# RK3399-AP register map
File version: 1
CPU: CA7 r0p1, little endian, MPU, FPU, I-cache, D-cache, VTOR, 4 interrupt priority bits, 0 interrupts
Registers are 32-bit, read-write, reset 0x0 unless marked. A register's access mark holds for its fields unless they carry their own. Offsets are from the block's base; [hi:lo] are bit positions; 'fields as' and 'values as' point back to an identical list.

## CRU (part 1 of 3)
Base 0xFF760000
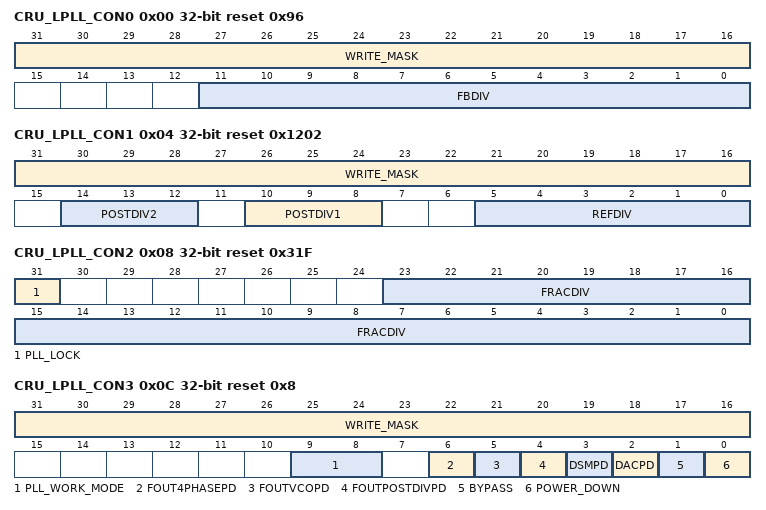
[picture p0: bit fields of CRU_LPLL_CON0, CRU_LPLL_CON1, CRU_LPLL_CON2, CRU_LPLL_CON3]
0x00 CRU_LPLL_CON0 access per field reset 0x96 — LPLL configuration register0
  [31:16] WRITE_MASK wo — write mask bits When every bit HIGH, enable the writing corresponding bit When every bit LOW, don\'t care the writing corresponding bit
  [11:0] FBDIV rw — Feedback Divide Value Valid divider settings are: [16, 3200] in integer mode [20, 320] in fractional mode Tips: no plus one operation
0x04 CRU_LPLL_CON1 access per field reset 0x1202 — LPLL configuration register1
  [31:16] WRITE_MASK wo — write mask bits When every bit HIGH, enable the writing corresponding bit When every bit LOW, don\'t care the writing corresponding bit
  [14:12] POSTDIV2 rw — Second Post Divide Value (1-7)
  [10:8] POSTDIV1 rw — First Post Divide Value (1-7)
  [5:0] REFDIV rw — Reference Clock Divide Value (1-63)
0x08 CRU_LPLL_CON2 access per field reset 0x31F — LPLL configuration register2
  [31] PLL_LOCK ro — PLL lock status 1\'b0: unlock 1\'b1: lock
  [23:0] FRACDIV rw — Fractional part of feedback divide (fraction = FRAC/2^24)
0x0C CRU_LPLL_CON3 access per field reset 0x8 — LPLL configuration register3
  [31:16] WRITE_MASK wo — write mask bits When every bit HIGH, enable the writing corresponding bit When every bit LOW, don\'t care the writing corresponding bit
  [9:8] PLL_WORK_MODE rw — PLL work mode select 2\'b00: Slow mode, clock from external 24MHz/26MHz OSC (default) 2\'b01: Normal mode, clock from PLL output 2\'b10: Deep slow mode, clock from external 32.768kHz
  [6] FOUT4PHASEPD rw — Power down 4-phase clocks and 2X, 3X, 4X clocks 1\'b0: no power down 1\'b1: power down
  [5] FOUTVCOPD rw — Power down buffered VCO clock 1\'b0: no power down 1\'b1: power down
  [4] FOUTPOSTDIVPD rw — Power down all outputs except for buffered VCO clock 1\'b0: no power down 1\'b1: power down
  [3] DSMPD rw — PLL saturation behavior enable 1\'b0: no power down 1\'b1: power down DSMPD = 1\'b1 ( modulator is disabled, "integer mode")
  [2] DACPD rw — Power down quantization noise cancellation DAC 1\'b0: no power down 1\'b1: power down
  [1] BYPASS rw — PLL Bypass. FREF bypasses PLL to FOUTPOSTDIV 1\'b0: no bypass 1\'b1: bypass
  [0] POWER_DOWN rw — Global power down 1\'b0: no power down 1\'b1: power down
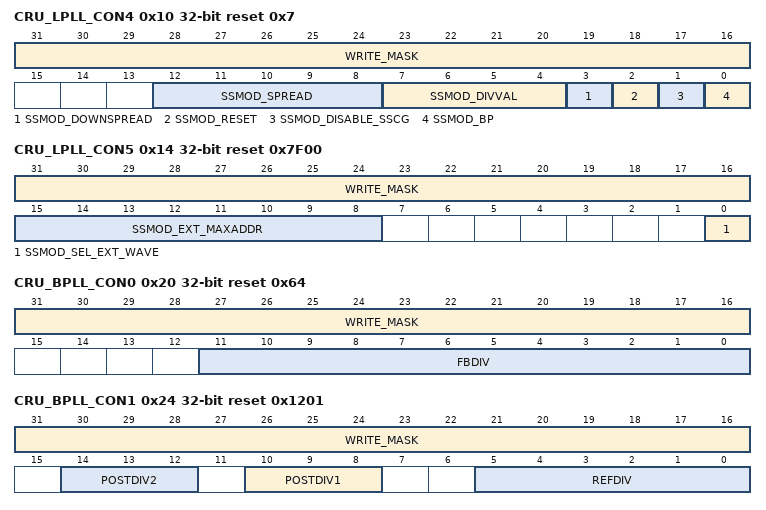
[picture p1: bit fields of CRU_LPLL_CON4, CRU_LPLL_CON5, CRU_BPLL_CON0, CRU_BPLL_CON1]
0x10 CRU_LPLL_CON4 access per field reset 0x7 — LPLL configuration register4
  [31:16] WRITE_MASK wo — write mask bits When every bit HIGH, enable the writing corresponding bit When every bit LOW, don\'t care the writing corresponding bit
  [12:8] SSMOD_SPREAD rw — spread amplitude % = 0.1 * SPREAD[4:0]
  [7:4] SSMOD_DIVVAL rw — Divider required to set the modulation frequency Divider required to set the modulation frequency
  [3] SSMOD_DOWNSPREAD rw — Selects center spread or downs pread 1\'b0: center spread 1\'b1: down spread
  [2] SSMOD_RESET rw — Reset modulator state 1\'b0: no reset 1\'b1: reset
  [1] SSMOD_DISABLE_SSCG rw — Bypass SSMOD by module 1\'b0: no bypass 1\'b1: bypass
  [0] SSMOD_BP rw — Bypass SSMOD by integration 1\'b0: no bypass 1\'b1: bypass
0x14 CRU_LPLL_CON5 access per field reset 0x7F00 — LPLL configuration register5
  [31:16] WRITE_MASK wo — write mask bits When every bit HIGH, enable the writing corresponding bit When every bit LOW, don\'t care the writing corresponding bit
  [15:8] SSMOD_EXT_MAXADDR rw — External wave table data inputs (0-255)
  [0] SSMOD_SEL_EXT_WAVE rw — select external wave 1\'b0: no select ext_wave 1\'b1: select ext_wave
0x20 CRU_BPLL_CON0 access per field reset 0x64 — BPLL configuration register0
  fields as CRU_LPLL_CON0
0x24 CRU_BPLL_CON1 access per field reset 0x1201 — BPLL configuration register1
  fields as CRU_LPLL_CON1
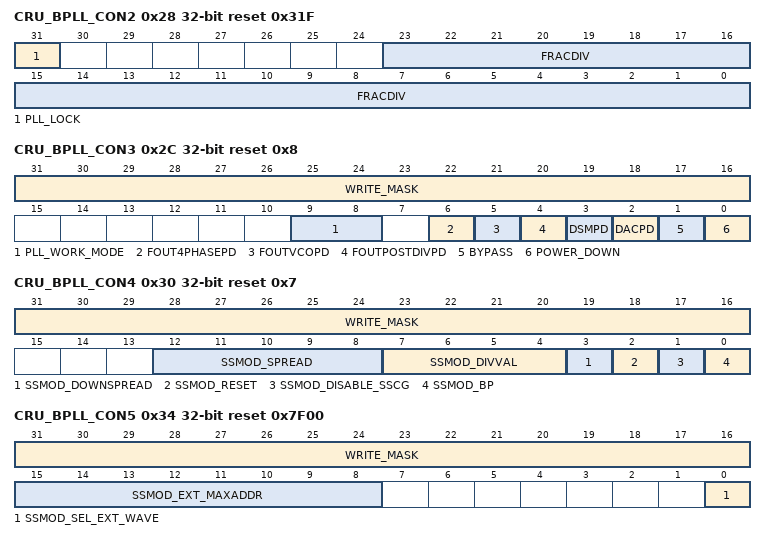
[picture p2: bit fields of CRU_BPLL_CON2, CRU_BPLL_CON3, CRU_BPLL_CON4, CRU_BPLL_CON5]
0x28 CRU_BPLL_CON2 access per field reset 0x31F — BPLL configuration register2
  fields as CRU_LPLL_CON2
0x2C CRU_BPLL_CON3 access per field reset 0x8 — BPLL configuration register3
  fields as CRU_LPLL_CON3
0x30 CRU_BPLL_CON4 access per field reset 0x7 — BPLL configuration register4
  fields as CRU_LPLL_CON4
0x34 CRU_BPLL_CON5 access per field reset 0x7F00 — BPLL configuration register5
  fields as CRU_LPLL_CON5
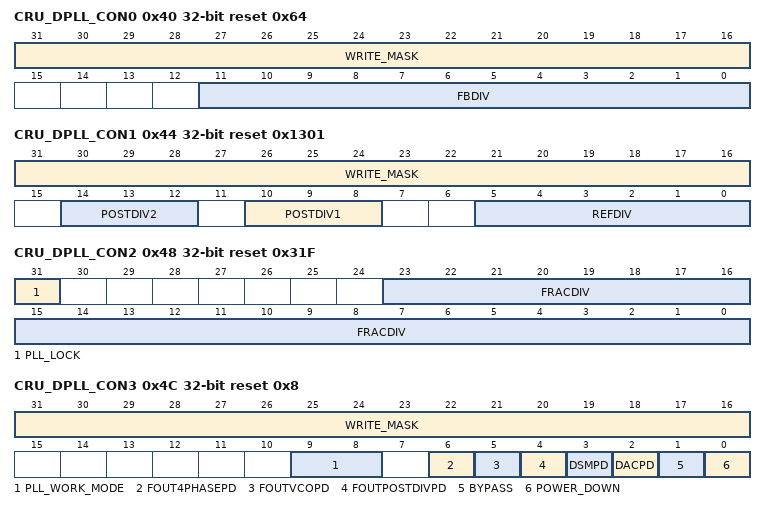
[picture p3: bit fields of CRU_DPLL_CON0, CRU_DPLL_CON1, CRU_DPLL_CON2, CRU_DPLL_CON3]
0x40 CRU_DPLL_CON0 access per field reset 0x64 — DPLL configuration register0
  fields as CRU_LPLL_CON0
0x44 CRU_DPLL_CON1 access per field reset 0x1301 — DPLL configuration register1
  fields as CRU_LPLL_CON1
0x48 CRU_DPLL_CON2 access per field reset 0x31F — DPLL configuration register2
  fields as CRU_LPLL_CON2
0x4C CRU_DPLL_CON3 access per field reset 0x8 — DPLL configuration register3
  fields as CRU_LPLL_CON3
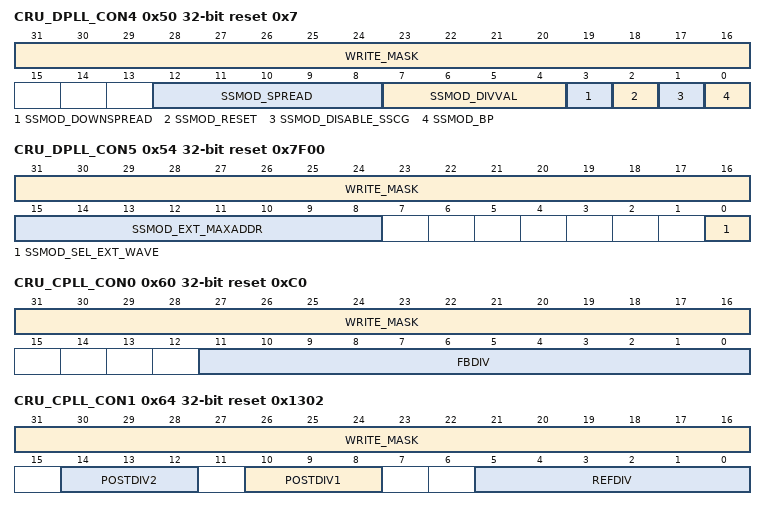
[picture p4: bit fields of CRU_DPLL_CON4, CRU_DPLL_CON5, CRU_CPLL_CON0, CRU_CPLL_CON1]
0x50 CRU_DPLL_CON4 access per field reset 0x7 — DPLL configuration register4
  fields as CRU_LPLL_CON4
0x54 CRU_DPLL_CON5 access per field reset 0x7F00 — DPLL configuration register5
  fields as CRU_LPLL_CON5
0x60 CRU_CPLL_CON0 access per field reset 0xC0 — CPLL configuration register0
  fields as CRU_LPLL_CON0
0x64 CRU_CPLL_CON1 access per field reset 0x1302 — CPLL configuration register1
  fields as CRU_LPLL_CON1
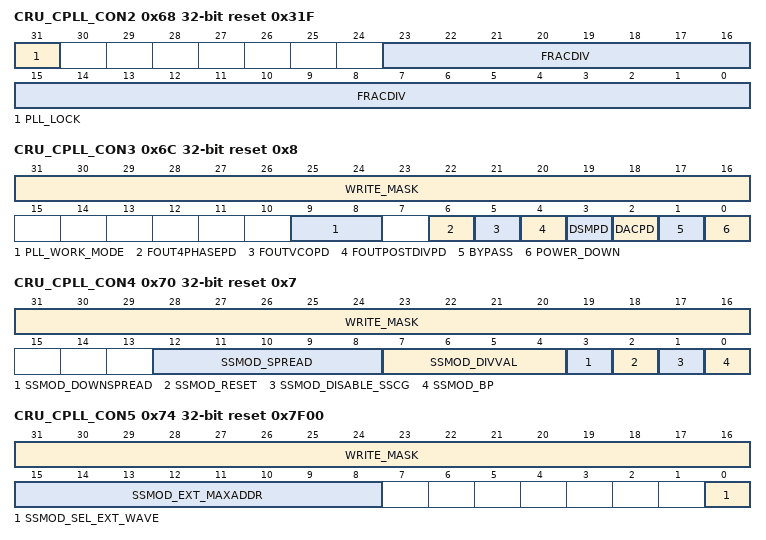
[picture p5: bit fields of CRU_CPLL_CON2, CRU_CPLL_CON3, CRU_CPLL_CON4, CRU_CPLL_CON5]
0x68 CRU_CPLL_CON2 access per field reset 0x31F — CPLL configuration register2
  fields as CRU_LPLL_CON2
0x6C CRU_CPLL_CON3 access per field reset 0x8 — CPLL configuration register3
  fields as CRU_LPLL_CON3
0x70 CRU_CPLL_CON4 access per field reset 0x7 — CPLL configuration register4
  fields as CRU_LPLL_CON4
0x74 CRU_CPLL_CON5 access per field reset 0x7F00 — CPLL configuration register5
  fields as CRU_LPLL_CON5
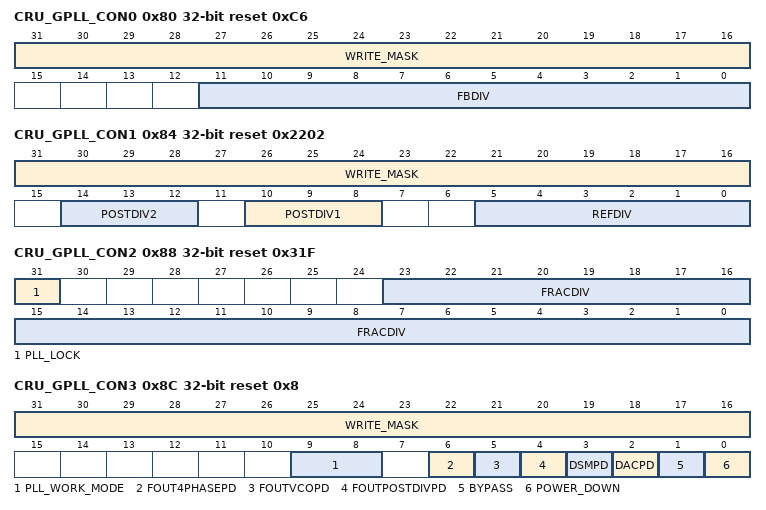
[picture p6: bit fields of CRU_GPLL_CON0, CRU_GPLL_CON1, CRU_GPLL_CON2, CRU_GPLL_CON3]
0x80 CRU_GPLL_CON0 access per field reset 0xC6 — GPLL configuration register0
  fields as CRU_LPLL_CON0
0x84 CRU_GPLL_CON1 access per field reset 0x2202 — GPLL configuration register1
  fields as CRU_LPLL_CON1
0x88 CRU_GPLL_CON2 access per field reset 0x31F — GPLL configuration register2
  fields as CRU_LPLL_CON2
0x8C CRU_GPLL_CON3 access per field reset 0x8 — GPLL configuration register3
  fields as CRU_LPLL_CON3
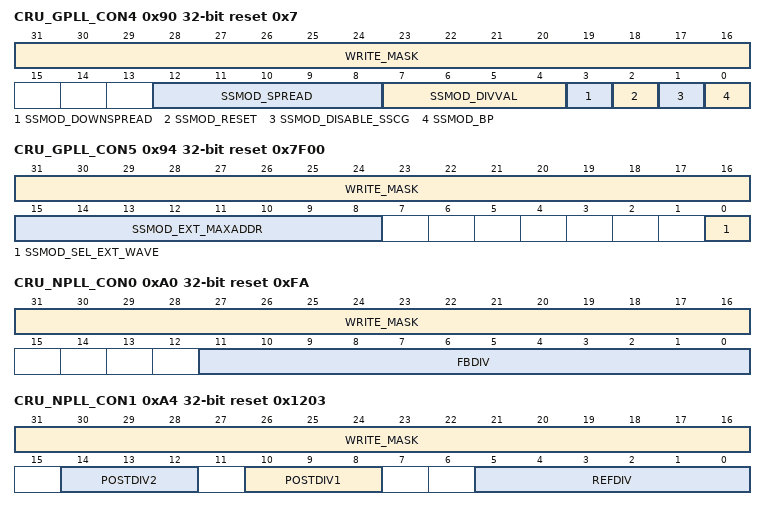
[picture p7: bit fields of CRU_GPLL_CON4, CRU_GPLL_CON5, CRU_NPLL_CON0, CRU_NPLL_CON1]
0x90 CRU_GPLL_CON4 access per field reset 0x7 — GPLL configuration register4
  fields as CRU_LPLL_CON4
0x94 CRU_GPLL_CON5 access per field reset 0x7F00 — GPLL configuration register5
  fields as CRU_LPLL_CON5
0xA0 CRU_NPLL_CON0 access per field reset 0xFA — NPLL configuration register0
  fields as CRU_LPLL_CON0
0xA4 CRU_NPLL_CON1 access per field reset 0x1203 — NPLL configuration register1
  fields as CRU_LPLL_CON1
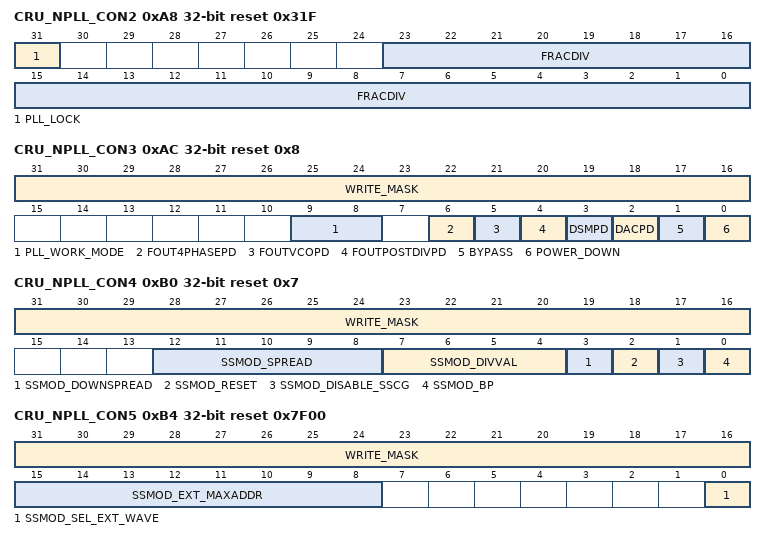
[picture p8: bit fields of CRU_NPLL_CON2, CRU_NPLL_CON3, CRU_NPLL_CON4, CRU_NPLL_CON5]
0xA8 CRU_NPLL_CON2 access per field reset 0x31F — NPLL configuration register2
  fields as CRU_LPLL_CON2
0xAC CRU_NPLL_CON3 access per field reset 0x8 — NPLL configuration register3
  fields as CRU_LPLL_CON3
0xB0 CRU_NPLL_CON4 access per field reset 0x7 — NPLL configuration register4
  fields as CRU_LPLL_CON4
0xB4 CRU_NPLL_CON5 access per field reset 0x7F00 — NPLL configuration register5
  fields as CRU_LPLL_CON5
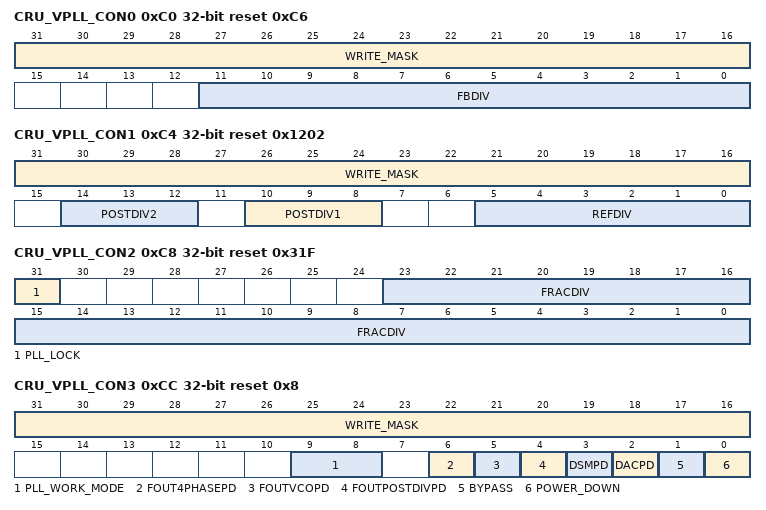
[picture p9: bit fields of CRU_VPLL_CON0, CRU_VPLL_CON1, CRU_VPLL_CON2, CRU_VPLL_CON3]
0xC0 CRU_VPLL_CON0 access per field reset 0xC6 — VPLL configuration register0
  fields as CRU_LPLL_CON0
0xC4 CRU_VPLL_CON1 access per field reset 0x1202 — VPLL configuration register1
  fields as CRU_LPLL_CON1
0xC8 CRU_VPLL_CON2 access per field reset 0x31F — VPLL configuration register2
  fields as CRU_LPLL_CON2
0xCC CRU_VPLL_CON3 access per field reset 0x8 — VPLL configuration register3
  fields as CRU_LPLL_CON3
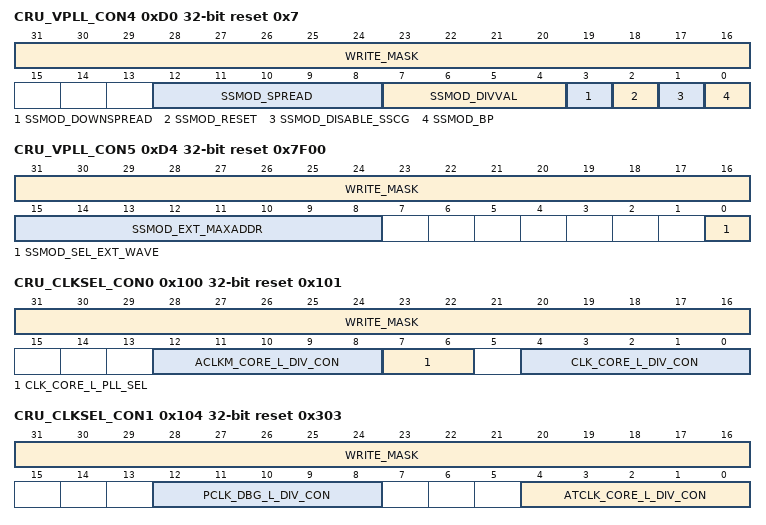
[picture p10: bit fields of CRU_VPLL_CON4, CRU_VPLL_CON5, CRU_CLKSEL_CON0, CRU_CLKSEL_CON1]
0xD0 CRU_VPLL_CON4 access per field reset 0x7 — VPLL configuration register4
  fields as CRU_LPLL_CON4
0xD4 CRU_VPLL_CON5 access per field reset 0x7F00 — VPLL configuration register5
  fields as CRU_LPLL_CON5
0x100 CRU_CLKSEL_CON0 access per field reset 0x101 — Internal clock select and divide register0
  [31:16] WRITE_MASK wo — write mask bits When every bit HIGH, enable the writing corresponding bit When every bit LOW, don\'t care the writing corresponding bit
  [12:8] ACLKM_CORE_L_DIV_CON rw — aclkm_core_l divider control register clk=clk_src/(div_con+1)
  [7:6] CLK_CORE_L_PLL_SEL rw — clk_core_l clock source select control register 2\'b00:LPLL 2\'b01:BPLL 2\'b10:DPLL 2\'b11:GPLL
  [4:0] CLK_CORE_L_DIV_CON rw — clk_core_l divider control register clk=clk_src/(div_con+1)
0x104 CRU_CLKSEL_CON1 access per field reset 0x303 — Internal clock select and divide register1
  [31:16] WRITE_MASK wo — write mask bits When every bit HIGH, enable the writing corresponding bit When every bit LOW, don\'t care the writing corresponding bit
  [12:8] PCLK_DBG_L_DIV_CON rw — pclk_dbg_l divider control register clk=clk_src/(div_con+1)
  [4:0] ATCLK_CORE_L_DIV_CON rw — atclk_core_l divider control register clk=clk_src/(div_con+1)
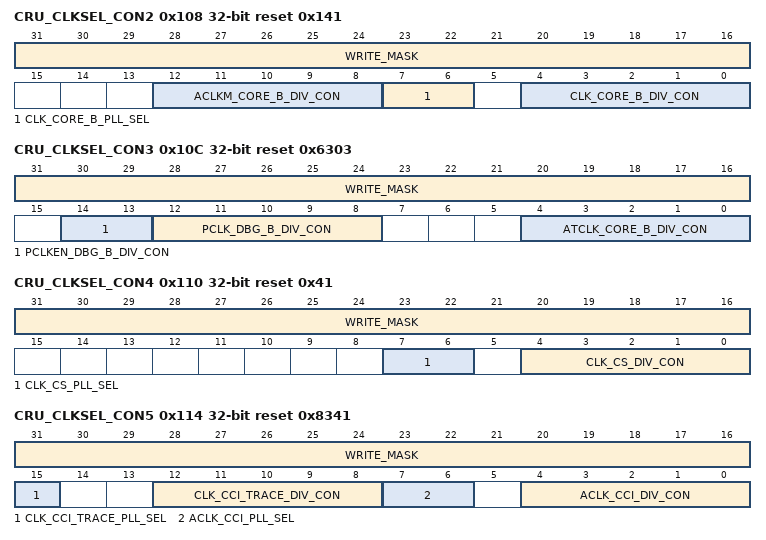
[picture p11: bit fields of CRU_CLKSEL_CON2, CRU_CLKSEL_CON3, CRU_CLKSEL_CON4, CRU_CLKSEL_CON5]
0x108 CRU_CLKSEL_CON2 access per field reset 0x141 — Internal clock select and divide register2
  [31:16] WRITE_MASK wo — write mask bits When every bit HIGH, enable the writing corresponding bit When every bit LOW, don\'t care the writing corresponding bit
  [12:8] ACLKM_CORE_B_DIV_CON rw — aclkm_core_b divider control register clk=clk_src/(div_con+1)
  [7:6] CLK_CORE_B_PLL_SEL rw — clk_core_b clock source select control register 2\'b00:LPLL 2\'b01:BPLL 2\'b10:DPLL 2\'b11:GPLL
  [4:0] CLK_CORE_B_DIV_CON rw — clk_core_b divider control register clk=clk_src/(div_con+1)
0x10C CRU_CLKSEL_CON3 access per field reset 0x6303 — Internal clock select and divide register3
  [31:16] WRITE_MASK wo — write mask bits When every bit HIGH, enable the writing corresponding bit When every bit LOW, don\'t care the writing corresponding bit
  [14:13] PCLKEN_DBG_B_DIV_CON rw — pclken_dbg_b divider control register clk=clk_src/(div_con+1)
  [12:8] PCLK_DBG_B_DIV_CON rw — pclk_dbg_b divider control register clk=clk_src/(div_con+1)
  [4:0] ATCLK_CORE_B_DIV_CON rw — atclk_core_b divider control register clk=clk_src/(div_con+1)
0x110 CRU_CLKSEL_CON4 access per field reset 0x41 — Internal clock select and divide register4
  [31:16] WRITE_MASK wo — write mask bits When every bit HIGH, enable the writing corresponding bit When every bit LOW, don\'t care the writing corresponding bit
  [7:6] CLK_CS_PLL_SEL rw — clk_cs clock source select control register 2\'b00:CPLL 2\'b01:GPLL 2\'b1x:NPLL
  [4:0] CLK_CS_DIV_CON rw — clk_cs divider control register clk=clk_src/(div_con+1)
0x114 CRU_CLKSEL_CON5 access per field reset 0x8341 — Internal clock select and divide register5
  [31:16] WRITE_MASK wo — write mask bits When every bit HIGH, enable the writing corresponding bit When every bit LOW, don\'t care the writing corresponding bit
  [15] CLK_CCI_TRACE_PLL_SEL rw — clk_cci_trace clock source select control register 1\'b0:CPLL 1\'b1:GPLL
  [12:8] CLK_CCI_TRACE_DIV_CON rw — clk_cci_trace divider control register clk=clk_src/(div_con+1)
  [7:6] ACLK_CCI_PLL_SEL rw — aclk_cci clock source select control register 2\'b00:CPLL 2\'b01:GPLL 2\'b10:NPLL 2\'b11:VPLL
  [4:0] ACLK_CCI_DIV_CON rw — aclk_cci divider control register clk=clk_src/(div_con+1)
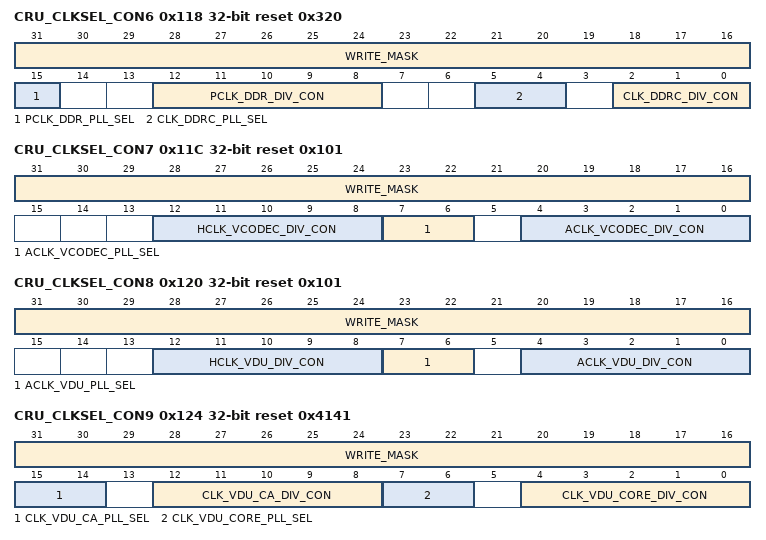
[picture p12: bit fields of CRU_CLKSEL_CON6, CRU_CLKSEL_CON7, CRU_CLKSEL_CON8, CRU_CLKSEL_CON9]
0x118 CRU_CLKSEL_CON6 access per field reset 0x320 — Internal clock select and divide register6
  [31:16] WRITE_MASK wo — write mask bits When every bit HIGH, enable the writing corresponding bit When every bit LOW, don\'t care the writing corresponding bit
  [15] PCLK_DDR_PLL_SEL rw — pclk_ddr clock source select control register 1\'b0:CPLL 1\'b1:GPLL
  [12:8] PCLK_DDR_DIV_CON rw — pclk_ddr divider control register clk=clk_src/(div_con+1)
  [5:4] CLK_DDRC_PLL_SEL rw — clk_ddrc clock source select control register 2\'b00:LPLL 2\'b01:BPLL 2\'b10:DPLL 2\'b11:GPLL
  [2:0] CLK_DDRC_DIV_CON rw — clk_ddrc divider control register clk=clk_src/(div_con+1)
0x11C CRU_CLKSEL_CON7 access per field reset 0x101 — Internal clock select and divide register7
  [31:16] WRITE_MASK wo — write mask bits When every bit HIGH, enable the writing corresponding bit When every bit LOW, don\'t care the writing corresponding bit
  [12:8] HCLK_VCODEC_DIV_CON rw — hclk_vcodec divider control register clk=clk_src/(div_con+1)
  [7:6] ACLK_VCODEC_PLL_SEL rw — aclk_vcodec clock source select control register 2\'b00:CPLL 2\'b01:GPLL 2\'b10:NPLL 2\'b11:PPLL
  [4:0] ACLK_VCODEC_DIV_CON rw — aclk_vcodec divider control register clk=clk_src/(div_con+1)
0x120 CRU_CLKSEL_CON8 access per field reset 0x101 — Internal clock select and divide register8
  [31:16] WRITE_MASK wo — write mask bits When every bit HIGH, enable the writing corresponding bit When every bit LOW, don\'t care the writing corresponding bit
  [12:8] HCLK_VDU_DIV_CON rw — hclk_vdu divider control register clk=clk_src/(div_con+1)
  [7:6] ACLK_VDU_PLL_SEL rw — aclk_vdu clock source select control register 2\'b00:CPLL 2\'b01:GPLL 2\'b10:NPLL 2\'b11:PPLL
  [4:0] ACLK_VDU_DIV_CON rw — aclk_vdu divider control register clk=clk_src/(div_con+1)
0x124 CRU_CLKSEL_CON9 access per field reset 0x4141 — Internal clock select and divide register9
  [31:16] WRITE_MASK wo — write mask bits When every bit HIGH, enable the writing corresponding bit When every bit LOW, don\'t care the writing corresponding bit
  [15:14] CLK_VDU_CA_PLL_SEL rw — clk_vdu_ca clock source select control register 2\'b00:CPLL 2\'b01:GPLL 2\'b1x:NPLL
  [12:8] CLK_VDU_CA_DIV_CON rw — clk_vdu_ca divider control register clk=clk_src/(div_con+1)
  [7:6] CLK_VDU_CORE_PLL_SEL rw — clk_vdu_core clock source select control register 2\'b00:CPLL 2\'b01:GPLL 2\'b1x:NPLL
  [4:0] CLK_VDU_CORE_DIV_CON rw — clk_vdu_core divider control register clk=clk_src/(div_con+1)
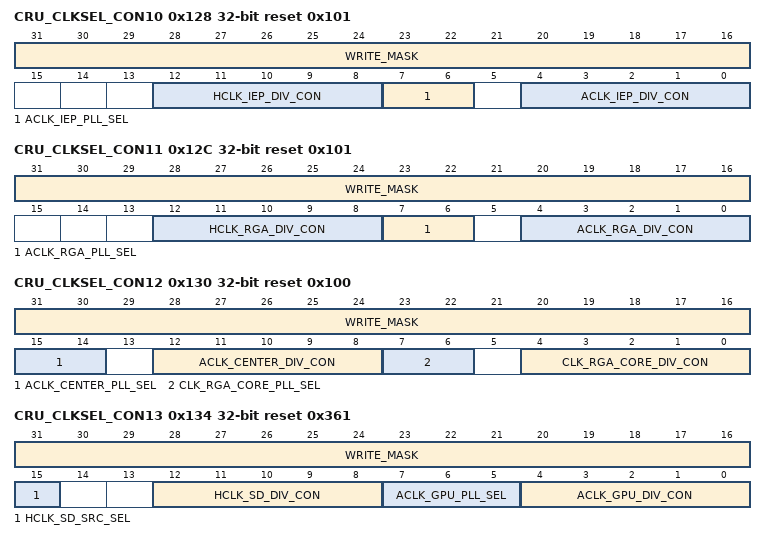
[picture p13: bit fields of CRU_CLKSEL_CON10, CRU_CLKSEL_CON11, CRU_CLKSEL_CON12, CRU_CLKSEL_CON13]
0x128 CRU_CLKSEL_CON10 access per field reset 0x101 — Internal clock select and divide register10
  [31:16] WRITE_MASK wo — write mask bits When every bit HIGH, enable the writing corresponding bit When every bit LOW, don\'t care the writing corresponding bit
  [12:8] HCLK_IEP_DIV_CON rw — hclk_iep divider control register clk=clk_src/(div_con+1)
  [7:6] ACLK_IEP_PLL_SEL rw — aclk_iep clock source select control register 2\'b00:CPLL 2\'b01:GPLL 2\'b10:NPLL 2\'b11:PPLL
  [4:0] ACLK_IEP_DIV_CON rw — aclk_iep divider control register clk=clk_src/(div_con+1)
0x12C CRU_CLKSEL_CON11 access per field reset 0x101 — Internal clock select and divide register11
  [31:16] WRITE_MASK wo — write mask bits When every bit HIGH, enable the writing corresponding bit When every bit LOW, don\'t care the writing corresponding bit
  [12:8] HCLK_RGA_DIV_CON rw — hclk_rga divider control register clk=clk_src/(div_con+1)
  [7:6] ACLK_RGA_PLL_SEL rw — aclk_rga clock source select control register 2\'b00:CPLL 2\'b01:GPLL 2\'b10:NPLL 2\'b11:PPLL
  [4:0] ACLK_RGA_DIV_CON rw — aclk_rga divider control register clk=clk_src/(div_con+1)
0x130 CRU_CLKSEL_CON12 access per field reset 0x100 — Internal clock select and divide register12
  [31:16] WRITE_MASK wo — write mask bits When every bit HIGH, enable the writing corresponding bit When every bit LOW, don\'t care the writing corresponding bit
  [15:14] ACLK_CENTER_PLL_SEL rw — aclk_center clock source select control register 2\'b00:CPLL 2\'b01:GPLL 2\'b1x:NPLL
  [12:8] ACLK_CENTER_DIV_CON rw — aclk_center divider control register clk=clk_src/(div_con+1)
  [7:6] CLK_RGA_CORE_PLL_SEL rw — clk_rga_core clock source select control register 2\'b00:CPLL 2\'b01:GPLL 2\'b10:NPLL 2\'b11:PPLL
  [4:0] CLK_RGA_CORE_DIV_CON rw — clk_rga_core divider control register clk=clk_src/(div_con+1)
0x134 CRU_CLKSEL_CON13 access per field reset 0x361 — Internal clock select and divide register13
  [31:16] WRITE_MASK wo — write mask bits When every bit HIGH, enable the writing corresponding bit When every bit LOW, don\'t care the writing corresponding bit
  [15] HCLK_SD_SRC_SEL rw — hclk_sd clock source select control register 1\'b0:CPLL 1\'b1:GPLL
  [12:8] HCLK_SD_DIV_CON rw — hclk_sd divider control register clk=clk_src/(div_con+1)
  [7:5] ACLK_GPU_PLL_SEL rw — aclk_gpu clock source select control register 3\'b000:PPLL 3\'b001:CPLL 3\'b010:GPLL 3\'b011:NPLL 3\'b100:USB_480M
  [4:0] ACLK_GPU_DIV_CON rw — aclk_gpu divider control register clk=clk_src/(div_con+1)
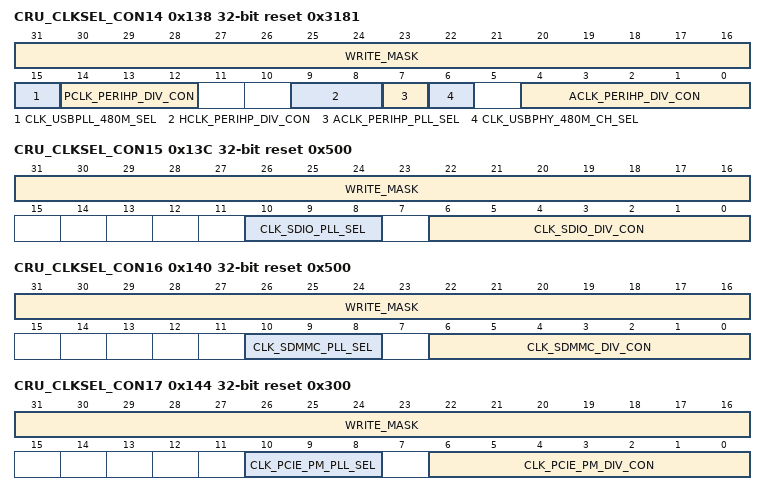
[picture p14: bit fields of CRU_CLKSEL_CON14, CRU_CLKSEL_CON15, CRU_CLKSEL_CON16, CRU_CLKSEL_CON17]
0x138 CRU_CLKSEL_CON14 access per field reset 0x3181 — Internal clock select and divide register14
  [31:16] WRITE_MASK wo — write mask bits When every bit HIGH, enable the writing corresponding bit When every bit LOW, don\'t care the writing corresponding bit
  [15] CLK_USBPLL_480M_SEL rw — clk_usbpll_480m_sel clock select control register 1\'b0:xin_24m 1\'b1:clk_usbphy_480m
  [14:12] PCLK_PERIHP_DIV_CON rw — pclk_perihp divider control register clk=aclk_perihp/(div_con+1)
  [9:8] HCLK_PERIHP_DIV_CON rw — hclk_perihp divider control register clk=aclk_perihp/(div_con+1)
  [7] ACLK_PERIHP_PLL_SEL rw — aclk_perihp clock source select control register 1\'b0:CPLL 1\'b1:GPLL
  [6] CLK_USBPHY_480M_CH_SEL rw — clk_usbphy_480m clock channel select control register 1\'b0:usb_phy0_480m 1\'b1:usb_phy1_480m
  [4:0] ACLK_PERIHP_DIV_CON rw — aclk_perihp divider control register clk=clk_src/(div_con+1)
0x13C CRU_CLKSEL_CON15 access per field reset 0x500 — Internal clock select and divide register15
  [31:16] WRITE_MASK wo — write mask bits When every bit HIGH, enable the writing corresponding bit When every bit LOW, don\'t care the writing corresponding bit
  [10:8] CLK_SDIO_PLL_SEL rw — clk_sdio clock source select control register 3\'b000:CPLL 3\'b001:GPLL 3\'b010:NPLL 3\'b011:PPLL 3\'b100:USB_480M 3\'b101:xin_24m
  [6:0] CLK_SDIO_DIV_CON rw — clk_sdio divider control register clk=clk_src/(div_con+1)
0x140 CRU_CLKSEL_CON16 access per field reset 0x500 — Internal clock select and divide register16
  [31:16] WRITE_MASK wo — write mask bits When every bit HIGH, enable the writing corresponding bit When every bit LOW, don\'t care the writing corresponding bit
  [10:8] CLK_SDMMC_PLL_SEL rw — clk_sdmmc clock source select control register 3\'b000:CPLL 3\'b001:GPLL 3\'b010:NPLL 3\'b011:PPLL 3\'b100:USB_480M 3\'b101:xin_24m
  [6:0] CLK_SDMMC_DIV_CON rw — clk_sdmmc divider control register clk=clk_src/(div_con+1)
0x144 CRU_CLKSEL_CON17 access per field reset 0x300 — Internal clock select and divide register17
  [31:16] WRITE_MASK wo — write mask bits When every bit HIGH, enable the writing corresponding bit When every bit LOW, don\'t care the writing corresponding bit
  [10:8] CLK_PCIE_PM_PLL_SEL rw — clk_pcie_pm clock source select control register 3\'b000:CPLL 3\'b001:GPLL 3\'b010:NPLL 3\'b011:xin_24m 3\'b1xx:reserved
  [6:0] CLK_PCIE_PM_DIV_CON rw — clk_pcie_pm divider control register clk=clk_src/(div_con+1)
0x148 CRU_CLKSEL_CON18 access per field reset 0x4A87 — Internal clock select and divide register18
  [31:16] WRITE_MASK wo — write mask bits When every bit HIGH, enable the writing corresponding bit When every bit LOW, don\'t care the writing corresponding bit
  [15:11] CLK_PCIEPHY_REF100M_DIV_CON rw — clk_pciephy_ref100m divider control register clk=clk_src/(div_con+1)
  [10] CLK_PCIEPHY_REF_SEL rw — clk_pciephy_ref clock select control register 1\'b0:clk_pcie_ref24m 1\'b1:clk_pcie_ref100m
  [9:8] CLK_PCIE_CORE_PLL_SEL rw — clk_pcie_core clock source select control register 2\'b00:CPLL 2\'b01:GPLL 2\'b1x:NPLL
  [7] CLK_PCIE_CORE_CLK_SEL rw — clk_pcie_core clock select control register 1\'b0:clk_pcie_core 1\'b1:pipe_clk_pcie from PCIE PHY
  [6:0] CLK_PCIE_CORE_DIV_CON rw — clk_pcie_core divider control register clk=clk_src/(div_con+1)
0x14C CRU_CLKSEL_CON19 access per field reset 0x100 — Internal clock select and divide register19
  [31:16] WRITE_MASK wo — write mask bits When every bit HIGH, enable the writing corresponding bit When every bit LOW, don\'t care the writing corresponding bit
  [10:8] PCLK_GMAC_DIV_CON rw — pclk_gmac divider control register clk=clk_src/(div_con+1)
  [4] CLK_RMII_SRC_SEL rw — clk_rmii_src clock select control register 1\'b0:clk_mac_divout 1\'b1:rmii_clkin from IO
  [1:0] CLK_HSICPHY_PLL_SEL rw — clk_hsicphy clock source select control register 2\'b00:CPLL 2\'b01:GPLL 2\'b10:NPLL 2\'b11:USB_480M
0x150 CRU_CLKSEL_CON20 access per field reset 0x9303 — Internal clock select and divide register20
  [31:16] WRITE_MASK wo — write mask bits When every bit HIGH, enable the writing corresponding bit When every bit LOW, don\'t care the writing corresponding bit
  [15:14] CLK_GMAC_PLL_SEL rw — clk_gmac clock source select control register 2\'b00:CPLL 2\'b01:GPLL 2\'b1x:NPLL
  [12:8] CLK_GMAC_DIV_CON rw — clk_gmac divider control register clk=clk_src/(div_con+1)
  [7] ACLK_GMAC_PLL_SEL rw — aclk_gmac clock source select control register 1\'b0:CPLL 1\'b1:GPLL
  [4:0] ACLK_GMAC_DIV_CON rw — aclk_gmac divider control register clk=clk_src/(div_con+1)
0x154 CRU_CLKSEL_CON21 access per field reset 0x3 — Internal clock select and divide register21
  [31:16] WRITE_MASK wo — write mask bits When every bit HIGH, enable the writing corresponding bit When every bit LOW, don\'t care the writing corresponding bit
  [7] ACLK_EMMC_PLL_SEL rw — aclk_emmc clock source select control register 1\'b0:CPLL 1\'b1:GPLL
  [4:0] ACLK_EMMC_DIV_CON rw — aclk_emmc divider control register clk=clk_src/(div_con+1)
0x158 CRU_CLKSEL_CON22 access per field reset 0x400 — Internal clock select and divide register22
  [31:16] WRITE_MASK wo — write mask bits When every bit HIGH, enable the writing corresponding bit When every bit LOW, don\'t care the writing corresponding bit
  [10:8] CLK_EMMC_PLL_SEL rw — clk_emmc clock source select control register 3\'b000:CPLL 3\'b001:GPLL 3\'b010:NPLL 3\'b011:USB_480M 3\'b1xx:xin_24m
  [6:0] CLK_EMMC_DIV_CON rw — clk_emmc divider control register clk=clk_src/(div_con+1)
0x15C CRU_CLKSEL_CON23 access per field reset 0x3181 — Internal clock select and divide register23
  [31:16] WRITE_MASK wo — write mask bits When every bit HIGH, enable the writing corresponding bit When every bit LOW, don\'t care the writing corresponding bit
  [14:12] PCLK_PERILP0_DIV_CON rw — perilp0_pclk divider control register clk=aclk_perilp0/(div_con+1)
  [9:8] HCLK_PERILP0_DIV_CON rw — perilp0_hclk divider control register clk=aclk_perilp0/(div_con+1)
  [7] ACLK_PERILP0_PLL_SEL rw — aclk_perilp0 clock source select control register 1\'b0:CPLL 1\'b1:GPLL
  [4:0] ACLK_PERILP0_DIV_CON rw — aclk_perilp0 divider control register clk=clk_src/(div_con+1)
0x160 CRU_CLKSEL_CON24 access per field reset 0x8103 — Internal clock select and divide register24
  [31:16] WRITE_MASK wo — write mask bits When every bit HIGH, enable the writing corresponding bit When every bit LOW, don\'t care the writing corresponding bit
  [15] FCLK_CM0S_PLL_SEL rw — fclk_cm0s clock source select control register 1\'b0:CPLL 1\'b1:GPLL
  [12:8] FCLK_CM0S_DIV_CON rw — fclk_cm0s divider control register clk=clk_src/(div_con+1)
  [7:6] CLK_CRYPTO0_PLL_SEL rw — clk_crypto0 clock source select control register 2\'b00:CPLL 2\'b01:GPLL 2\'b10:PPLL
  [4:0] CLK_CRYPTO0_DIV_CON rw — clk_crypto0 divider control register clk=clk_src/(div_con+1)
0x164 CRU_CLKSEL_CON25 access per field reset 0x183 — Internal clock select and divide register25
  [31:16] WRITE_MASK wo — write mask bits When every bit HIGH, enable the writing corresponding bit When every bit LOW, don\'t care the writing corresponding bit
  [10:8] PCLK_PERILP1_DIV_CON rw — pclk_perilp1 divider control register clk=hclk_perilp1/(div_con+1)
  [7] HCLK_PERILP1_PLL_SEL rw — hclk_perilp1 clock source select control register 1\'b0:CPLL 1\'b1:GPLL
  [4:0] HCLK_PERILP1_DIV_CON rw — hclk_perilp1 divider control register clk=clk_src/(div_con+1)
0x168 CRU_CLKSEL_CON26 access per field reset 0x103 — Internal clock select and divide register26
  [31:16] WRITE_MASK wo — write mask bits When every bit HIGH, enable the writing corresponding bit When every bit LOW, don\'t care the writing corresponding bit
  [15:8] CLK_SARADC_DIV_CON rw — clk_saradc divider control register clk=clk_src/(div_con+1)
  [7:6] CLK_CRYPTO1_PLL_SEL rw — clk_crypto1 clock source select control register 2\'b00:CPLL 2\'b01:GPLL 2\'b10:PPLL
  [4:0] CLK_CRYPTO1_DIV_CON rw — clk_crypto1 divider control register clk=clk_src/(div_con+1)
0x16C CRU_CLKSEL_CON27 access per field reset 0x2DC — Internal clock select and divide register27
  [31:16] WRITE_MASK wo — write mask bits When every bit HIGH, enable the writing corresponding bit When every bit LOW, don\'t care the writing corresponding bit
  [15] CLK_TSADC_SEL rw — clk tsadc clock select control register 1\'b0:xin_24m 1\'b1:clk_32k
  [9:0] CLK_TSADC_DIV_CON rw — clk tsadc divider control register clk=clk_src/(div_con+1)
0x170 CRU_CLKSEL_CON28 access per field reset 0x300 — Internal clock select and divide register28
  [31:16] WRITE_MASK wo — write mask bits When every bit HIGH, enable the writing corresponding bit When every bit LOW, don\'t care the writing corresponding bit
  [9:8] CLK_I2S0_SEL rw — clk_i2s0 clock select control register 2\'b00:clk_i2s0_divout 2\'b01:clk_i2s0_frac 2\'b10:clkin_i2s from IO 2\'b11:clk_12m
  [7] CLK_I2S0_PLL_SEL rw — clk_i2s0 clock source select control register 1\'b0:CPLL 1\'b1:GPLL
  [6:0] CLK_I2S0_DIV_CON rw — clk_i2s0 divider control register clk=clk_src/(div_con+1)
0x174 CRU_CLKSEL_CON29 access per field reset 0x300 — Internal clock select and divide register29
  [31:16] WRITE_MASK wo — write mask bits When every bit HIGH, enable the writing corresponding bit When every bit LOW, don\'t care the writing corresponding bit
  [9:8] CLK_I2S1_SEL rw — clk_i2s1 clock select control register 2\'b00:clk_i2s1_divout 2\'b01:clk_i2s1_frac 2\'b10:clkin_i2s from IO 2\'b11:clk_12m
  [7] CLK_I2S1_PLL_SEL rw — clk_i2s1 clock source select control register 1\'b0:CPLL 1\'b1:GPLL
  [6:0] CLK_I2S1_DIV_CON rw — clk_i2s1 divider control register clk=clk_src/(div_con+1)
0x178 CRU_CLKSEL_CON30 access per field reset 0x300 — Internal clock select and divide register30
  [31:16] WRITE_MASK wo — write mask bits When every bit HIGH, enable the writing corresponding bit When every bit LOW, don\'t care the writing corresponding bit
  [9:8] CLK_I2S2_SEL rw — clk_i2s2 clock select control register 2\'b00:clk_i2s2_divout 2\'b01:clk_i2s2_frac 2\'b10:clkin_i2s2 from IO 2\'b11:clk_12m
  [7] CLK_I2S2_PLL_SEL rw — clk_i2s2 clock source select control register 1\'b0:CPLL 1\'b1:GPLL
  [6:0] CLK_I2S2_DIV_CON rw — clk_i2s2 divider control register clk=clk_src/(div_con+1)
0x17C CRU_CLKSEL_CON31 access per field — Internal clock select and divide register31
  [31:16] WRITE_MASK wo — write mask bits When every bit HIGH, enable the writing corresponding bit When every bit LOW, don\'t care the writing corresponding bit
  [2] CLK_I2SOUT_SEL rw — clk_i2sout clock select control register 1\'b0:clk_i2s 1\'b1:clk_12m
  [1:0] CLK_I2S_CH_SEL rw — clk_i2s_ch clock select control register 2\'b00:clk_i2s0 2\'b01:clk_i2s1 2\'b10:clk_i2s2
0x180 CRU_CLKSEL_CON32 access per field reset 0x6300 — Internal clock select and divide register32
  [31:16] WRITE_MASK wo — write mask bits When every bit HIGH, enable the writing corresponding bit When every bit LOW, don\'t care the writing corresponding bit
  [15] CLK_DPTX_SPDIF_REC_PLL_SEL rw — clk_dptx_spdif_rec clock source select control register 1\'b0:CPLL 1\'b1:GPLL
  [14:13] CLK_SPDIF_8CH_CLK_SEL rw — clk_spdif_8ch clock select control register 2\'b00:clk_spdif_divout 2\'b01:clk_spdif_frac 2\'b10:clkin_spdif from IO SAME AS clkin_i2s 2\'b11:clk_12m
  [12:8] CLK_DPTX_SPDIF_REC_DIV_CON rw — clk_dptx_spdif_rec divider control register clk=clk_src/(div_con+1)
  [7] CLK_SPDIF_8CH_PLL_SEL rw — clk_spdif_8ch clock source select control register 1\'b0:CPLL 1\'b1:GPLL
  [6:0] CLK_SPDIF_8CH_PLL_DIV_CON rw — clk_spdif_8ch_pll divider control register clk=clk_src/(div_con+1)
0x184 CRU_CLKSEL_CON33 access per field reset 0x200 — Internal clock select and divide register33
  [31:16] WRITE_MASK wo — write mask bits When every bit HIGH, enable the writing corresponding bit When every bit LOW, don\'t care the writing corresponding bit
  [15] CLK_UART_PLL_SEL rw — clk_uart clock source select control register 1\'b0:CPLL 1\'b1:GPLL
  [13:12] CLK_UART0_SRC_SEL rw — clk_uart0_src clock select control register 2\'b00:CPLL 2\'b01:GPLL 2\'b1x:USB_480M
  [9:8] CLK_UART0_SEL rw — clk_uart0 clock select control register 2\'b00:clk_uart0_divout 2\'b01:clk_uart0_frac 2\'b10:xin_24m
  [6:0] CLK_UART0_DIV_CON rw — clk_uart0 divider control register clk=clk_src/(div_con+1)
0x188 CRU_CLKSEL_CON34 access per field reset 0x200 — Internal clock select and divide register34
  [31:16] CLK_WRITE_MASK wo — write mask bits When every bit HIGH, enable the writing corresponding bit When every bit LOW, don\'t care the writing corresponding bit
  [9:8] CLK_UART1_SEL rw — clk_uart1 clock select control register 2\'b00:clk_uart1_divout 2\'b01:clk_uart1_frac 2\'b10:xin_24m
  [6:0] CLK_UART1_DIV_CON rw — clk_uart1 divider control register clk=clk_src/(div_con+1)
0x18C CRU_CLKSEL_CON35 access per field reset 0x200 — Internal clock select and divide register35
  [31:16] WRITE_MASK wo — write mask bits When every bit HIGH, enable the writing corresponding bit When every bit LOW, don\'t care the writing corresponding bit
  [9:8] CLK_UART2_SEL rw — clk_uart2 clock select control register 2\'b00:clk_uart2_divout 2\'b01:clk_uart2_frac 2\'b10:xin_24m
  [6:0] CLK_UART2_DIV_CON rw — clk_uart2 divider control register clk=clk_src/(div_con+1)
0x190 CRU_CLKSEL_CON36 access per field reset 0x200 — Internal clock select and divide register36
  [31:16] WRITE_MASK wo — write mask bits When every bit HIGH, enable the writing corresponding bit When every bit LOW, don\'t care the writing corresponding bit
  [9:8] CLK_UART3_SEL rw — clk_uart3 clock select control register 2\'b00:clk_uart3_divout 2\'b01:clk_uart3_frac 2\'b10:xin_24m
  [6:0] CLK_UART3_DIV_CON rw — clk_uart3 divider control register clk=clk_src/(div_con+1)
0x198 CRU_CLKSEL_CON38 access per field reset 0x3F3F — Internal clock select and divide register38
  [31:16] WRITE_MASK wo — write mask bits When every bit HIGH, enable the writing corresponding bit When every bit LOW, don\'t care the writing corresponding bit
  [15:14] CLK_TESTOUT2_PLL_SEL rw — clk_testout2 clock source select control register 2\'b00:CPLL 2\'b01:GPLL 2\'b1x:NPLL
  [13] CLK_TESTOUT2_CLK_SEL rw — clk_testout2 clock select control register 1\'b0:clk_testout_src 1\'b1:xin_24m
  [12:8] CLK_TESTOUT2_DIV_CON rw — clk_testout2 divider control register clk=clk_src/(div_con+1)
  [7:6] CLK_TESTOUT1_PLL_SEL rw — clk_testout1 clock source select control register 2\'b00:CPLL 2\'b01:GPLL 2\'b1x:NPLL
  [5] CLK_TESTOUT1_CLK_SEL rw — clk_testout1 clock select control register 1\'b0:clk_testout_src 1\'b1:xin_24m
  [4:0] CLK_TESTOUT1_DIV_CON rw — clk_testout1 divider control register clk=clk_src/(div_con+1)
0x19C CRU_CLKSEL_CON39 access per field reset 0x41 — Internal clock select and divide register39
  [31:16] WRITE_MASK wo — write mask bits When every bit HIGH, enable the writing corresponding bit When every bit LOW, don\'t care the writing corresponding bit
  [7:6] ACLK_USB3_PLL_SEL rw — aclk_usb3 clock source select control register 2\'b00:CPLL 2\'b01:GPLL 2\'b1x:NPLL
  [4:0] ACLK_USB3_DIV_CON rw — aclk_usb3 divider control register clk=clk_src/(div_con+1)
0x1A0 CRU_CLKSEL_CON40 access per field — Internal clock select and divide register40
  [31:16] WRITE_MASK wo — write mask bits When every bit HIGH, enable the writing corresponding bit When every bit LOW, don\'t care the writing corresponding bit
  [15] CLK_USB3_OTG0_SUSPEND_SRC_SEL rw — clk_usb3_otg0_suspend_src clock select control register 1\'b0:xin_24m 1\'b1:clk_32k
  [9:0] CLK_USB3_OTG0_SUSPEND_DIV_CON rw — clk_usb3_otg0_suspend divider control register clk=clk_src/(div_con+1)
0x1A4 CRU_CLKSEL_CON41 access per field — Internal clock select and divide register41
  [31:16] WRITE_MASK wo — write mask bits When every bit HIGH, enable the writing corresponding bit When every bit LOW, don\'t care the writing corresponding bit
  [15] CLK_USB3_OTG1_SUSPEND_SRC_SEL rw — clk_usb3_otg1_suspend_src clock select control register 1\'b0:xin_24m 1\'b1:clk_32k
  [9:0] CLK_USB3_OTG1_SUSPEND_DIV_CON rw — clk_usb3_otg1_suspend divider control register clk=clk_src/(div_con+1)
0x1A8 CRU_CLKSEL_CON42 access per field reset 0x101 — Internal clock select and divide register42
  [31:16] WRITE_MASK wo — write mask bits When every bit HIGH, enable the writing corresponding bit When every bit LOW, don\'t care the writing corresponding bit
  [15:14] ACLK_HDCP_PLL_SEL rw — aclk_hdcp clock source select control register 2\'b00:CPLL 2\'b01:GPLL 2\'b10:PPLL
  [12:8] ACLK_HDCP_DIV_CON rw — aclk_hdcp divider control register clk=clk_src/(div_con+1)
  [7:6] ACLK_VIO_PLL_SEL rw — aclk_vio clock source select control register 2\'b00:CPLL 2\'b01:GPLL 2\'b10:PPLL
  [4:0] ACLK_VIO_DIV_CON rw — aclk_vio divider control register clk=clk_src/(div_con+1)
0x1AC CRU_CLKSEL_CON43 access per field reset 0x421 — Internal clock select and divide register43
  [31:16] WRITE_MASK wo — write mask bits When every bit HIGH, enable the writing corresponding bit When every bit LOW, don\'t care the writing corresponding bit
  [14:10] PCLK_HDCP_DIV_CON rw — pclk_hdcp divider control register clk=clk_src/(div_con+1)
  [9:5] HCLK_HDCP_DIV_CON rw — hclk_hdcp divider control register clk=clk_src/(div_con+1)
  [4:0] PCLK_VIO_DIV_CON rw — pclk_vio divider control register clk=clk_src/(div_con+1)
0x1B0 CRU_CLKSEL_CON44 access per field reset 0x700 — Internal clock select and divide register44
  [31:16] WRITE_MASK wo — write mask bits When every bit HIGH, enable the writing corresponding bit When every bit LOW, don\'t care the writing corresponding bit
  [15] PCLK_EDP_PLL_SEL rw — pclk_edp clock source select control register 1\'b0:CPLL 1\'b1:GPLL
  [13:8] PCLK_EDP_DIV_CON rw — pclk_edp divider control register clk=clk_src/(div_con+1)
0x1B4 CRU_CLKSEL_CON45 access per field reset 0x2DC — Internal clock select and divide register45
  [31:16] WRITE_MASK wo — write mask bits When every bit HIGH, enable the writing corresponding bit When every bit LOW, don\'t care the writing corresponding bit
  [15] CLK_HDMI_CEC_SRC_SEL rw — clk_hdmi_cec_src clock select control register 1\'b0:clk_32k 1\'b1:xin_24m
  [9:0] CLK_HDMI_CEC_DIV_CON rw — clk_hdmi_cec divider control register clk=clk_src/(div_con+1)
0x1B8 CRU_CLKSEL_CON46 access per field reset 0x4 — Internal clock select and divide register46
  [31:16] WRITE_MASK wo — write mask bits When every bit HIGH, enable the writing corresponding bit When every bit LOW, don\'t care the writing corresponding bit
  [7:6] CLK_DP_CORE_PLL_SEL rw — clk_dp_core clock source select control register 2\'b00:NPLL 2\'b01:CPLL 2\'b10:GPLL
  [4:0] CLK_DP_CORE_DIV_CON rw — clk_dp_core divider control register clk=clk_src/(div_con+1)
0x1BC CRU_CLKSEL_CON47 access per field reset 0x102 — Internal clock select and divide register47
  [31:16] WRITE_MASK wo — write mask bits When every bit HIGH, enable the writing corresponding bit When every bit LOW, don\'t care the writing corresponding bit
  [12:8] HCLK_VOP0_DIV_CON rw — hclk_vop0 divider control register clk=clk_src/(div_con+1)
  [7:6] ACLK_VOP0_PLL_SEL rw — aclk_vop0 clock source select control register 2\'b00:VPLL 2\'b01:CPLL 2\'b10:GPLL 2\'b11:NPLL
  [4:0] ACLK_VOP0_DIV_CON rw — aclk_vop0 divider control register clk=clk_src/(div_con+1)
0x1C0 CRU_CLKSEL_CON48 access per field reset 0x102 — Internal clock select and divide register48
  [31:16] WRITE_MASK wo — write mask bits When every bit HIGH, enable the writing corresponding bit When every bit LOW, don\'t care the writing corresponding bit
  [12:8] HCLK_VOP1_DIV_CON rw — hclk_vop1 divider control register clk=clk_src/(div_con+1)
  [7:6] ACLK_VOP1_PLL_SEL rw — aclk_vop1 clock source select control register 2\'b00:VPLL 2\'b01:CPLL 2\'b10:GPLL 2\'b11:NPLL
  [4:0] ACLK_VOP1_DIV_CON rw — aclk_vop1 divider control register clk=clk_src/(div_con+1)
0x1C4 CRU_CLKSEL_CON49 access per field reset 0x1 — Internal clock select and divide register49
  [31:16] WRITE_MASK wo — write mask bits When every bit HIGH, enable the writing corresponding bit When every bit LOW, don\'t care the writing corresponding bit
  [11] DCLK_VOP0_DCLK_SEL rw — dclk_vop0 clock select control register 1\'b0:dclk_vop_divout 1\'b1:dclk_vop_frac
  [9:8] DCLK_VOP0_PLL_SEL rw — dclk_vop0 clock source select control register 2\'b00:VPLL 2\'b01:CPLL 2\'b1x:GPLL
  [7:0] DCLK_VOP0_DIV_CON rw — dclk_vop0 divider control register clk=clk_src/(div_con+1)
0x1C8 CRU_CLKSEL_CON50 access per field reset 0x3 — Internal clock select and divide register50
  [31:16] WRITE_MASK wo — write mask bits When every bit HIGH, enable the writing corresponding bit When every bit LOW, don\'t care the writing corresponding bit
  [11] DCLK_VOP1_DCLK_SEL rw — dclk_vop1 clock select control register 1\'b0:dclk_vop_divout 1\'b1:dclk_vop_frac
  [9:8] DCLK_VOP1_PLL_SEL rw — dclk_vop1 clock source select control register 2\'b00:VPLL 2\'b01:CPLL 2\'b1x:GPLL
  [7:0] DCLK_VOP1_DIV_CON rw — vop1 divider control register clk=clk_src/(div_con+1)
0x1CC CRU_CLKSEL_CON51 access per field reset 0x5 — Internal clock select and divide register51
  [31:16] WRITE_MASK wo — write mask bits When every bit HIGH, enable the writing corresponding bit When every bit LOW, don\'t care the writing corresponding bit
  [7:6] CLK_VOP0_PWM_SRC_SEL rw — vop0_pwm_src clock select control register 2\'b00:VPLL 2\'b01:CPLL 2\'b1x:GPLL
  [4:0] CLK_VOP0_PWM_DIV_CON rw — vop0_pwm divider control register clk=clk_src/(div_con+1)
0x1D0 CRU_CLKSEL_CON52 access per field reset 0x5 — Internal clock select and divide register52
  [31:16] WRITE_MASK wo — write mask bits When every bit HIGH, enable the writing corresponding bit When every bit LOW, don\'t care the writing corresponding bit
  [7:6] CLK_VOP1_PWM_SRC_SEL rw — vop1_pwm_src clock select control register 2\'b00:VPLL 2\'b01:CPLL 2\'b1x:GPLL
  [4:0] CLK_VOP1_PWM_DIV_CON rw — vop1_pwm divider control register clk=clk_src/(div_con+1)
0x1D4 CRU_CLKSEL_CON53 access per field reset 0x101 — Internal clock select and divide register53
  [31:16] WRITE_MASK wo — write mask bits When every bit HIGH, enable the writing corresponding bit When every bit LOW, don\'t care the writing corresponding bit
  [12:8] HCLK_ISP0_DIV_CON rw — hclk_isp0 divider control register clk=clk_src/(div_con+1)
  [7:6] ACLK_ISP0_PLL_SEL rw — aclk_isp0 clock source select control register 2\'b00:CPLL 2\'b01:GPLL 2\'b10:PPLL
  [4:0] ACLK_ISP0_DIV_CON rw — aclk_isp0 divider control register clk=clk_src/(div_con+1)
0x1D8 CRU_CLKSEL_CON54 access per field reset 0x101 — Internal clock select and divide register54
  [31:16] WRITE_MASK wo — write mask bits When every bit HIGH, enable the writing corresponding bit When every bit LOW, don\'t care the writing corresponding bit
  [12:8] HCLK_ISP1_DIV_CON rw — hclk_isp1 divider control register clk=clk_src/(div_con+1)
  [7:6] ACLK_ISP1_PLL_SEL rw — aclk_isp1 clock source select control register 2\'b00:CPLL 2\'b01:GPLL 2\'b10:PPLL
  [4:0] ACLK_ISP1_DIV_CON rw — aclk_isp1 divider control register clk=clk_src/(div_con+1)
0x1DC CRU_CLKSEL_CON55 access per field reset 0x8181 — Internal clock select and divide register55
  [31:16] WRITE_MASK wo — write mask bits When every bit HIGH, enable the writing corresponding bit When every bit LOW, don\'t care the writing corresponding bit
  [15:14] CLK_ISP1_PLL_SEL rw — clk_isp1 clock source select control register 2\'b00:CPLL 2\'b01:GPLL 2\'b1x:NPLL
  [12:8] CLK_ISP1_DIV_CON rw — clk_isp1 divider control register clk=clk_src/(div_con+1)
  [7:6] CLK_ISP0_PLL_SEL rw — clk_isp0 clock source select control register 2\'b00:CPLL 2\'b01:GPLL 2\'b1x:NPLL
  [4:0] CLK_ISP0_DIV_CON rw — clk_isp0 divider control register clk=clk_src/(div_con+1)
0x1E0 CRU_CLKSEL_CON56 access per field reset 0x320 — Internal clock select and divide register56
  [31:16] WRITE_MASK wo — write mask bits When every bit HIGH, enable the writing corresponding bit When every bit LOW, don\'t care the writing corresponding bit
  [15] ACLK_GIC_PLL_SEL rw — aclk_gic source select control register 1\'b0:CPLL 1\'b1:GPLL
  [12:8] ACLK_GIC_DIV_CON rw — aclk_gic divider control register clk=clk_src/(div_con+1)
  [7:6] CLK_CIF_PLL_SEL rw — clk_cif clock source select control register 2\'b00:CPLL 2\'b01:GPLL 2\'b1x:NPLL
  [5] CLK_CIF_CLK_SEL rw — clk_cif clock select control register 1\'b0:clk_cif_src 1\'b1:xin_24m
  [4:0] CLK_CIF_DIV_CON rw — clk_cif divider control register clk=clk_src/(div_con+1)
0x1E4 CRU_CLKSEL_CON57 access per field reset 0x5 — Internal clock select and divide register57
  [31:16] WRITE_MASK wo — write mask bits When every bit HIGH, enable the writing corresponding bit When every bit LOW, don\'t care the writing corresponding bit
  [15:6] CLKOUT_24M_DIV_CON rw — clkout_24m divider control register clk=clk_src/(div_con+1)
  [4:0] PCLK_ALIVE_DIV_CON rw — pclk_alive divider control register clk=clk_src/(div_con+1)
